# GD32E25x register map
File version: 1.0
CPU: CM23 r1p0, little endian, no MPU, no FPU, 2 interrupt priority bits
Registers are 32-bit, read-write, reset 0x0 unless marked. A register's access mark holds for its fields unless they carry their own. Offsets are from the block's base; [hi:lo] are bit positions; lines under a group give offsets from that group; {n}, {i} and the like mark numbered series.

## ADC — Analog to digital converter
Base 0x40012400
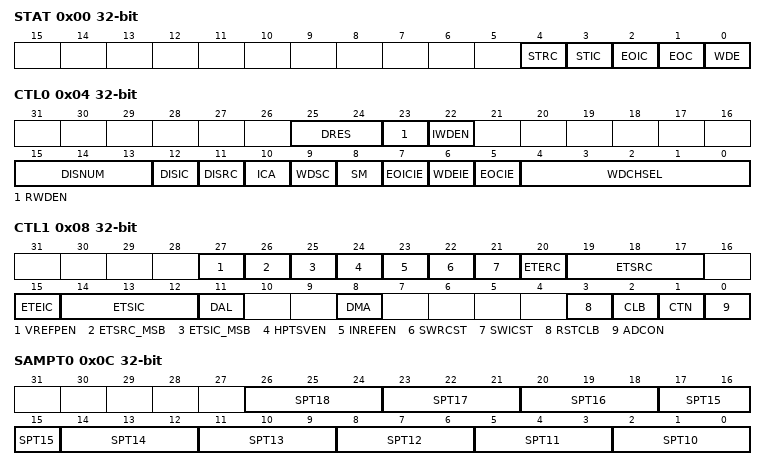
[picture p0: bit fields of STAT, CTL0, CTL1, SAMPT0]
0x00 STAT — status register
  [4] STRC — Start flag of regular channel group
  [3] STIC — Start flag of inserted channel group
  [2] EOIC — End of inserted group conversion flag
  [1] EOC — End of group conversion flag
  [0] WDE — Analog watchdog event flag
0x04 CTL0 — control register 0
  [25:24] DRES — ADC resolution
  [23] RWDEN — Regular channel analog watchdog enable
  [22] IWDEN — Inserted channel analog watchdog enable
  [15:13] DISNUM — Number of conversions in discontinuous mode
  [12] DISIC — Discontinuous mode on injected channels
  [11] DISRC — Discontinuous mode on regular channels
  [10] ICA — Inserted channel group convert automatically
  [9] WDSC — When in scan mode, analog watchdog is effective on a single channel
  [8] SM — Scan mode
  [7] EOICIE — Interrupt enable for EOIC
  [6] WDEIE — Interrupt enable for WDE
  [5] EOCIE — Interrupt enable for EOC
  [4:0] WDCHSEL — Analog watchdog channel select
0x08 CTL1 — control register 1
  [27] VREFPEN — Channel 18 (positive reference voltage) enable of ADC
  [26] ETSRC_MSB — External trigger select for regular channel
  [25] ETSIC_MSB — External trigger select for inserted channel
  [24] HPTSVEN — Channel 16 (high precision temperature sensor) enable of ADC
  [23] INREFEN — Channel 17 (internal reference voltage) enable of ADC
  [22] SWRCST — Start on regular channel
  [21] SWICST — Start on inserted channel
  [20] ETERC — External trigger enable for regular channel
  [19:17] ETSRC — External trigger select for regular channel
  [15] ETEIC — External trigger enable for inserted channels
  [14:12] ETSIC — External trigger select for inserted channel
  [11] DAL — Data alignment
  [8] DMA — DMA request enable
  [3] RSTCLB — Reset calibration
  [2] CLB — ADC calibration
  [1] CTN — Continuous mode
  [0] ADCON
0x0C SAMPT0 — Sampling time register 0
  [3n-28:3n-30] SPT{n} (n=10..18) — Channel {n} sample time selection
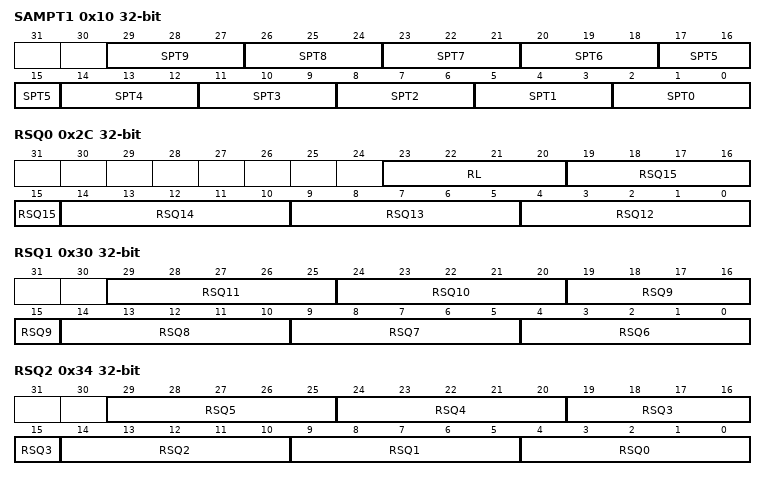
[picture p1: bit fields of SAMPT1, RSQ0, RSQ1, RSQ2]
0x10 SAMPT1 — Sampling time register 1
  [3n+2:3n] SPT{n} (n=1..9) — Channel {n} sample time selection
  [2:0] SPT0 — Channel 9 sample time selection
{0x14+4i} IOFF{i} (i=0..3) — Inserted channel data offset register {i}
  [11:0] IOFF — Data offset for injected channel x
0x24 WDHT reset 0xFFF — watchdog higher threshold register
  [11:0] WDHT — Analog watchdog high threshold
0x28 WDLT — watchdog low threshold register
  [11:0] WDLT — Analog watchdog lower threshold
0x2C RSQ0 — regular sequence register 0
  [23:20] RL — Regular channel sequence length
  [5n-56:5n-60] RSQ{n} (n=12..15) — {n}th conversion in regular sequence
0x30 RSQ1 — regular sequence register 1
  [5n-26:5n-30] RSQ{n} (n=6..11) — {n}th conversion in regular sequence
0x34 RSQ2 — regular sequence register 2
  [29:25] RSQ5 — 5th conversion in regular sequence
  [24:20] RSQ4 — 4th conversion in regular sequence
  [19:15] RSQ3 — 3rd conversion in regular sequence
  [14:10] RSQ2 — 2nd conversion in regular sequence
  [9:5] RSQ1 — 1st conversion in regular sequence
  [4:0] RSQ0 — conversion in regular sequence
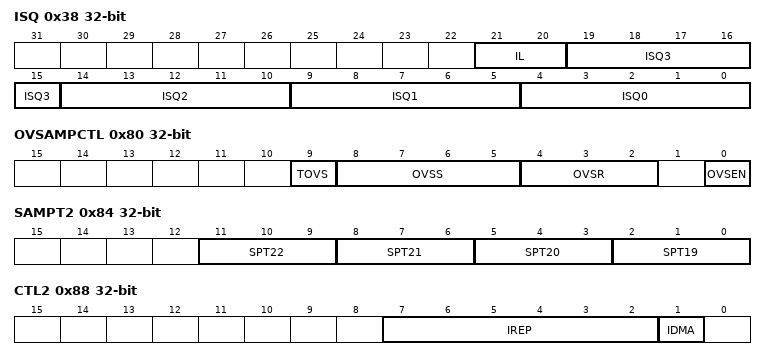
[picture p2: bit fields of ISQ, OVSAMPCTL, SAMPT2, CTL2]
0x38 ISQ — inserted sequence register
  [21:20] IL — Inserted sequence length
  [19:15] ISQ3 — 3rd conversion in inserted sequence
  [14:10] ISQ2 — 2nd conversion in inserted sequence
  [9:5] ISQ1 — 1st conversion in inserted sequence
  [4:0] ISQ0 — conversion in inserted sequence
{0x3C+4i} IDATA{i} ro (i=0..3) — inserted data register {i}
  [15:0] IDATAn — inserted data
0x4C RDATA ro — regular data register
  [15:0] RDATA — Regular data
0x80 OVSAMPCTL — ADC oversample control register
  [9] TOVS — Triggered Oversampling
  [8:5] OVSS — Oversampling shift
  [4:2] OVSR — Oversampling ratio
  [0] OVSEN — Oversampler Enable
0x84 SAMPT2 — Sample time register 2
  [3n-55:3n-57] SPT{n} (n=19..22) — Channel {n} sample time selection
0x88 CTL2 — control register 2
  [7:2] IREP — Inject group repeat times
  [1] IDMA — DMA request enable for Inject channel
